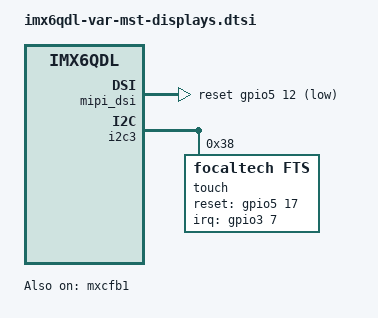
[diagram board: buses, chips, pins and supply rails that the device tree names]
/*
 * Copyright (C) 2015-2019 MS Tech.
 *
 * Author: Ron Donio. ron.d@ms-technologies.com
 *
 * This program is free software; you can redistribute it and/or modify
 * it under the terms of the GNU General Public License version 2 as
 * published by the Free Software Foundation.
 *
 * Capacitive MIPI DSI Display for MS Tech i.MX6Q board/
 */

&mipi_dsi {
	compatible = "fsl,imx6q-mipi-dsi";
	dev_id = <0x0>;
	disp_id = <0x1>;
	lcd_panel = "KD035HVTIA067";
//	disp-power-on-supply = <&reg_mipi_dsi_pwr_on>;
	reset-gpios = <&gpio5 12 GPIO_ACTIVE_LOW>;
	reset-delay-us = <50000>;
	status = "okay";
};

&mxcfb1 {
	compatible = "fsl,mxc_sdc_fb";
    disp_dev = "mipi_dsi";
    interface_pix_fmt = "RGB565";
    mode_str ="KD035HVTIA067";
    default_bpp = <16>;
    int_clk = <0>;
    lete_init = <0>;
    status = "okay";
};

&mipi_csi {
	status = "disabled";
};

&i2c3 {

	touch: focaltech@38 {
		compatible = "focaltech,fts";
		reg = <0x38>;
		interrupt-parent = <&gpio3>;
		interrupts = <7 0>;
		focaltech,panel-type = <FT6336G>;
		focaltech,reset-gpio = <&gpio5 17 0>;
		focaltech,irq-gpio = <&gpio3 7 0>;
		focaltech,max-touch-number = <5>;
		focaltech,display-coords =  <0 0 350 480>;

		focaltech,have-key;
		focaltech,key-number = <3>;
		focaltech,keys = <139 102 158>;
		focaltech,key-y-coord = <2000>;
		focaltech,key-x-coords = <200 600 800>;
	};

};
